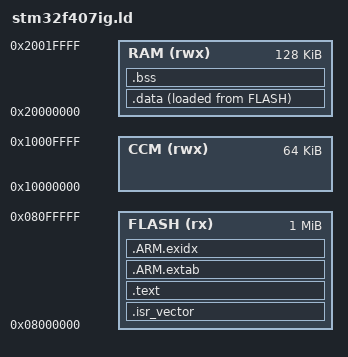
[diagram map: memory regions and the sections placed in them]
ENTRY(Reset_Handler)

MEMORY
{
    FLASH (rx)  : ORIGIN = 0x08000000, LENGTH = 1024K
    RAM   (rwx) : ORIGIN = 0x20000000, LENGTH = 128K
    CCM   (rwx) : ORIGIN = 0x10000000, LENGTH = 64K
}

_estack = ORIGIN(RAM) + LENGTH(RAM);
_stack_reserve = 4096;

SECTIONS
{
    .isr_vector : ALIGN(512)
    {
        KEEP(*(.isr_vector))
    } > FLASH
    .text : ALIGN(4)
    {
        *(.text .text.*)
        *(.rodata .rodata.*)
        . = ALIGN(4);
    } > FLASH
    .ARM.extab : { *(.ARM.extab* .gnu.linkonce.armextab.*) } > FLASH
    .ARM.exidx :
    {
        __exidx_start = .;
        *(.ARM.exidx* .gnu.linkonce.armexidx.*)
        __exidx_end = .;
    } > FLASH
    .data : ALIGN(4)
    {
        _sdata = .;
        *(.data .data.*)
        . = ALIGN(4);
        _edata = .;
    } > RAM AT > FLASH
    _sidata = LOADADDR(.data);
    .bss (NOLOAD) : ALIGN(4)
    {
        _sbss = .;
        *(.bss .bss.* COMMON)
        . = ALIGN(4);
        _ebss = .;
    } > RAM
    .ARM.attributes 0 : { *(.ARM.attributes) }
    /DISCARD/ : { *(.note*) *(.comment) }
    ASSERT(_ebss <= (_estack - _stack_reserve), "RAM overlaps 4KB stack reserve")
}
